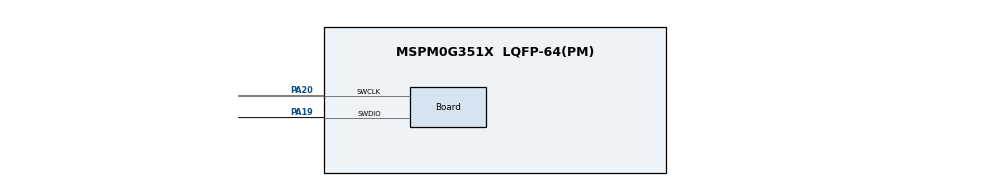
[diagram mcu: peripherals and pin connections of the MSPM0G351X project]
// == Generated by scaffold.py ==
// GPIO instance $name != pin $name, and every $name is globally unique.
//   WRONG: instance="LED", pin="LED"  -> Duplicate name error
//   OK:    instance="LED", pin="PIN"
// SDK example may carry extra pins (PB26/PB27/PB14 are occupied on this
// board) -- delete the ones you don't need.
// After SysConfig runs, grep ti_msp_dl_config.h to confirm macro names.

/**
 * @cliArgs --device "MSPM0G351X" --part "Default" --package "LQFP-64(PM)" --product "mspm0_sdk@2.05.01.01"
 * @versions {"tool":"1.24.0+4110"}
 */

const GPIO   = scripting.addModule("/ti/driverlib/GPIO", {}, false);
const GPIO1  = GPIO.addInstance();
const SYSCTL = scripting.addModule("/ti/driverlib/SYSCTL");

/* ---- 32 MHz default clock (no HFXT/PLL clock tree) ---- */
SYSCTL.forceDefaultClkConfig = true;

/* ---- Board: SWD debug ---- */
const Board = scripting.addModule("/ti/driverlib/Board", {}, false);
Board.peripheral.$assign = "DEBUGSS";
Board.peripheral.swclkPin.$assign = "PA20";
Board.peripheral.swdioPin.$assign = "PA19";

/* ---- OLED I2C: PA0=SDA, PA1=SCL (GPIO only; I2C0 init by OLED_driver.c) ---- */
GPIO1.$name = "OLED";
GPIO1.associatedPins.create(2);
GPIO1.associatedPins[0].$name = "SDA";
GPIO1.associatedPins[0].direction        = "OUTPUT";
GPIO1.associatedPins[0].initialValue     = "SET";
GPIO1.associatedPins[0].initialValue = "SET";
GPIO1.associatedPins[0].assignedPort = "PORTA";
GPIO1.associatedPins[0].assignedPin = "0";
GPIO1.associatedPins[0].ioStructure = "OD";
GPIO1.associatedPins[1].$name = "SCL";
GPIO1.associatedPins[1].direction        = "OUTPUT";
GPIO1.associatedPins[1].initialValue     = "SET";
GPIO1.associatedPins[1].initialValue = "SET";
GPIO1.associatedPins[1].assignedPort = "PORTA";
GPIO1.associatedPins[1].assignedPin = "1";
GPIO1.associatedPins[1].ioStructure = "OD";

const ProjectConfig = scripting.addModule("/ti/project_config/ProjectConfig", {}, false);
ProjectConfig.migrationCondition = true;
